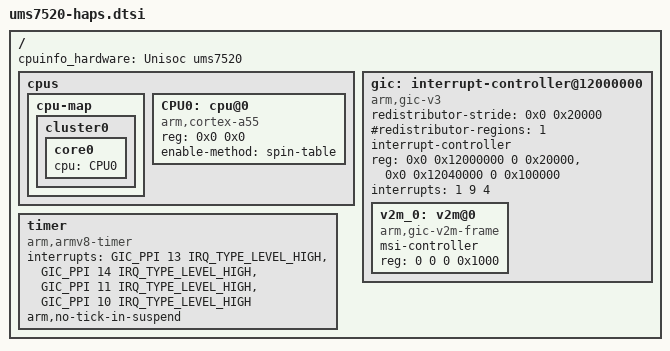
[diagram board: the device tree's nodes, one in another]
// SPDX-License-Identifier: (GPL-2.0+ OR MIT)
/*
 * Unisoc Qogirn6pro platform DTS file
 *
 * Copyright (C) 2019, Unisoc Communications Inc.
 */

#include "qogirn6pro-haps.dtsi"

/ {
	cpuinfo_hardware = "Unisoc ums7520";

	cpus {
		#address-cells = <2>;
		#size-cells = <0>;

		cpu-map {
			cluster0 {
				core0 {
					cpu = <&CPU0>;
				};
			};
		};

		CPU0: cpu@0 {
			device_type = "cpu";
			compatible = "arm,cortex-a55","arm,armv8";
			reg = <0x0 0x0>;
			enable-method = "spin-table";
		};
	};

	gic: interrupt-controller@12000000 {
		compatible = "arm,gic-v3";
		#interrupt-cells = <3>;
		#address-cells = <2>;
		#size-cells = <2>;
		ranges;
		redistributor-stride = <0x0 0x20000>;	/* 128KB stride */
		#redistributor-regions = <1>;
		interrupt-controller;
		reg = <0x0 0x12000000 0 0x20000>,	/* GICD */
			<0x0 0x12040000 0 0x100000>;	/* GICR */
		interrupts = <1 9 4>;
		v2m_0: v2m@0 {
			compatible = "arm,gic-v2m-frame";
			msi-controller;
			reg = <0 0 0 0x1000>;
		};
	};

	timer {
		compatible = "arm,armv8-timer";
		interrupts = <GIC_PPI 13 IRQ_TYPE_LEVEL_HIGH>, /* Physical Secure PPI */
			<GIC_PPI 14 IRQ_TYPE_LEVEL_HIGH>, /* Physical Non-Secure PPI */
			<GIC_PPI 11 IRQ_TYPE_LEVEL_HIGH>, /* Virtual PPI */
			<GIC_PPI 10 IRQ_TYPE_LEVEL_HIGH>; /* Hipervisor PPI */
		arm,no-tick-in-suspend;
	};
};
